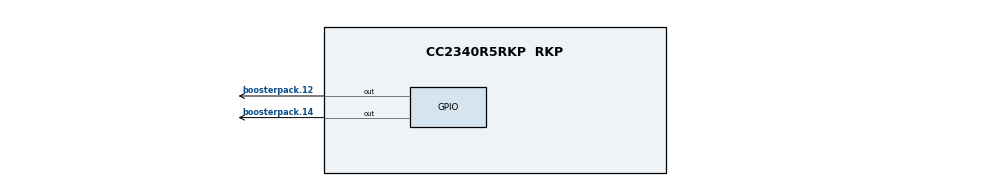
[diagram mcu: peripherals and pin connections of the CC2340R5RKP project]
/**
 * @cliArgs --board "/ti/boards/LP_EM_CC2340R5" --device "CC2340R5RKP" --part "Default" --package "RKP" --rtos "freertos" --product "simplelink_lowpower_f3_sdk@9.14.00.39"
 * @versions {"tool":"1.23.2+4156"}
 */

/**
 * Import the modules used in this configuration.
 */
const FreeRTOS = scripting.addModule("/freertos/FreeRTOS");
const CCFG     = scripting.addModule("/ti/devices/CCFG");
const rfdesign = scripting.addModule("/ti/devices/radioconfig/rfdesign");
const GPIO     = scripting.addModule("/ti/drivers/GPIO");
const GPIO1    = GPIO.addInstance();
const GPIO2    = GPIO.addInstance();
const GPIO3    = GPIO.addInstance();
const GPIO4    = GPIO.addInstance();
const GPIO5    = GPIO.addInstance();
const GPIO6    = GPIO.addInstance();
const NVS      = scripting.addModule("/ti/drivers/NVS", {}, false);
const NVS1     = NVS.addInstance();
const PWM      = scripting.addModule("/ti/drivers/PWM", {}, false);
const PWM1     = PWM.addInstance();
const Settings = scripting.addModule("/ti/posix/freertos/Settings");
const zigbee   = scripting.addModule("/ti/zigbee/zigbee");

/**
 * Write custom configuration values to the imported modules.
 */
FreeRTOS.heapSize       = 0x00001BBC;
FreeRTOS.timerStackSize = 0x00000100;

CCFG.ccfgTemplate.$name = "ti_devices_CCFG_CCFGCC23X0Template0";

GPIO1.$hardware = system.deviceData.board.components.LED_GREEN;
GPIO1.$name     = "CONFIG_GPIO_GLED";

GPIO2.$hardware = system.deviceData.board.components.LED_RED;
GPIO2.$name     = "CONFIG_GPIO_RLED";

GPIO3.$hardware        = system.deviceData.board.components["BTN-1"];
GPIO3.$name            = "CONFIG_GPIO_BTN1";
GPIO3.pull             = "Pull Up";
GPIO3.interruptTrigger = "Falling Edge";

GPIO4.$name            = "CONFIG_GPIO_BTN2";
GPIO4.pull             = "Pull Up";
GPIO4.interruptTrigger = "Falling Edge";

GPIO5.$name            = "CONFIG_GPIO_DALI_RX";
GPIO5.interruptTrigger = "Both Edges";
GPIO5.gpioPin.$assign  = "boosterpack.14";

GPIO6.$name              = "CONFIG_GPIO_DALI_TX";
GPIO6.initialOutputState = "High";
GPIO6.mode               = "Output";
GPIO6.gpioPin.$assign    = "boosterpack.12";

NVS1.$name                    = "CONFIG_NVS_INTERNAL";
NVS1.internalFlash.$name      = "ti_drivers_nvs_NVSLPF30";
NVS1.internalFlash.regionBase = 0x7D000;
NVS1.internalFlash.regionSize = 0x1000;

PWM1.$name                          = "CONFIG_PWM_0";
PWM1.timerObject.$name              = "CONFIG_LGPTIMER_0";
PWM1.timerObject.channel2Connection = "Pin";
PWM1.timerObject.timer.$assign      = "LGPT3";

zigbee.zigbeeRevision  = "r22";
zigbee.deviceType      = ["zr"];
zigbee.txPower         = "8";
zigbee.primaryChannels = [17];

const RNG       = scripting.addModule("/ti/drivers/RNG", {}, false);
RNG.rngPoolSize = 512;
scripting.suppress("This the default noise conditioning key provided by TI, which is acceptable per NIST SP 800-90B\\. However, TI recommends you change this default value to a custom random value for your product", RNG, "noiseConditioningKeyW3");

/**
 * Pinmux solution for unlocked pins/peripherals. This ensures that minor changes to the automatic solver in a future
 * version of the tool will not impact the pinmux you originally saw.  These lines can be completely deleted in order to
 * re-solve from scratch.
 */
GPIO1.gpioPin.$suggestSolution                 = "boosterpack.40";
GPIO2.gpioPin.$suggestSolution                 = "boosterpack.39";
GPIO3.gpioPin.$suggestSolution                 = "boosterpack.13";
GPIO4.gpioPin.$suggestSolution                 = "boosterpack.36";
PWM1.timerObject.timer.ch2Pin.$suggestSolution = "boosterpack.10";
